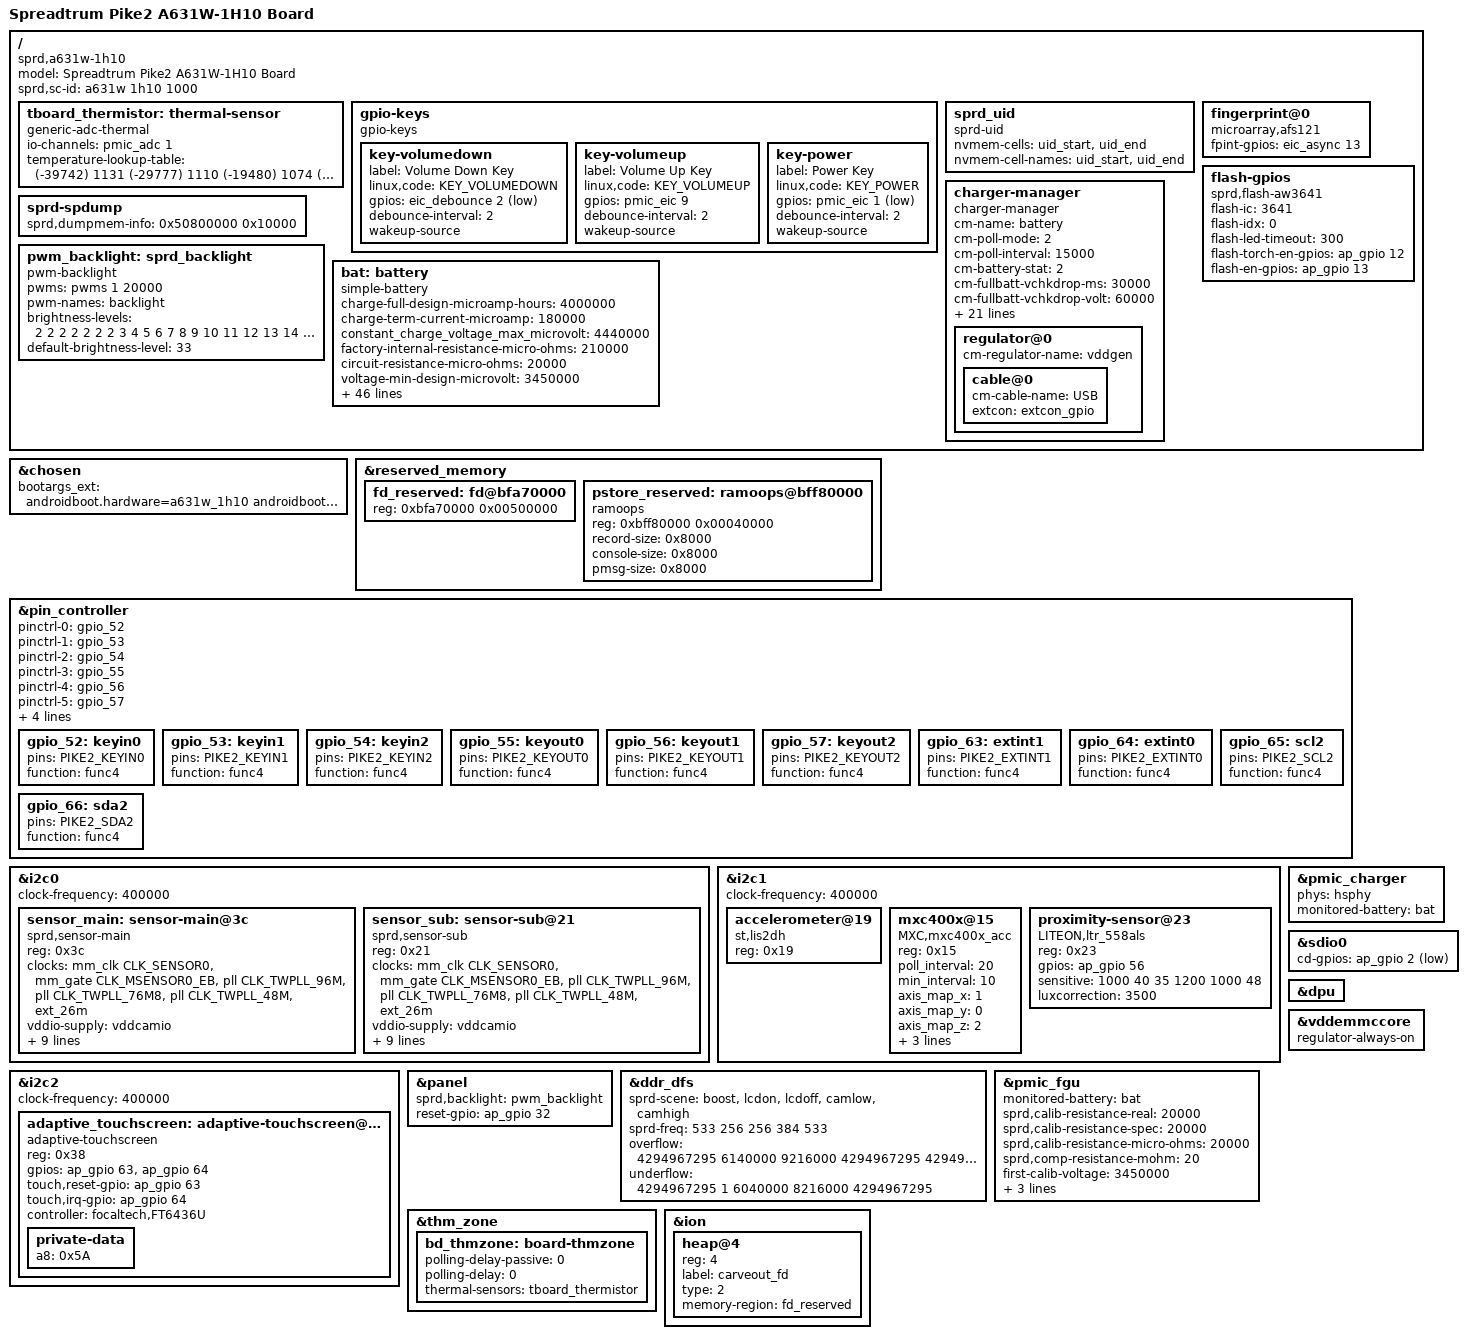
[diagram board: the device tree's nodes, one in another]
/*
 * Spreadtrum sharkle sp7731e board DTS file
 *
 * Copyright (C) 2019, Spreadtrum Communications Inc.
 *
 * This file is licensed under a dual GPLv2 or X11 license.
 */
/dts-v1/;
/plugin/;
#include <dt-bindings/input/input.h>
#include <dt-bindings/gpio/gpio.h>
#include <dt-bindings/clock/sprd,sc7731e-clk.h>
//#include "lcd/lcd_ili9881c_3lane_mipi_fhd.dtsi"
//#include "lcd/lcd_r61350_truly_mipi_hd_v2.dtsi"
#include "lcd/lcd_gc9503NP_mipi_jt.dtsi"
#include "lcd/lcd_dummy_mipi.dtsi"

/ {
	model = "Spreadtrum Pike2 A631W-1H10 Board";

	compatible = "sprd,a631w-1h10", "sprd,sc7731e";

	sprd,sc-id = "a631w 1h10 1000";

	/*
	* When create a new node, we should use the key word __overlay__,
	* otherwise u-boot can not analyze it.
	*/
	fragment {
		target-path = "/";
		__overlay__ {

			tboard_thermistor:thermal-sensor {
				compatible = "generic-adc-thermal";
				#thermal-sensor-cells = <0>;
				io-channels = <&pmic_adc 1>;
				io-channel-names = "sensor-channel";
				temperature-lookup-table = <    (-39742) 1131
								(-29777) 1110
								(-19480) 1074
								(-4679) 983
								10110 838
								24805 654
								44922 413
								54903 316
								64895 238
								74884 178
								84883 133
								94883 100
								104880 75
								114889 57
								124872 43 >;
			};

			gpio-keys {
				compatible = "gpio-keys";

				key-volumedown {
					label = "Volume Down Key";
					linux,code = <KEY_VOLUMEDOWN>;
					gpios = <&eic_debounce 2 GPIO_ACTIVE_LOW>;
					debounce-interval = <2>;
					wakeup-source;
				};

				key-volumeup {
					label = "Volume Up Key";
					linux,code = <KEY_VOLUMEUP>;
					gpios = <&pmic_eic 9 GPIO_ACTIVE_HIGH>;
					debounce-interval = <2>;
					wakeup-source;
				};

				key-power {
					label = "Power Key";
					linux,code = <KEY_POWER>;
					gpios = <&pmic_eic 1 GPIO_ACTIVE_LOW>;
					debounce-interval = <2>;
					wakeup-source;
				};
			};
			sprd_uid {
				compatible = "sprd-uid";
				nvmem-cells = <&uid_start>, <&uid_end>;
				nvmem-cell-names = "uid_start", "uid_end";
			};
			fingerprint@0 {
				compatible = "microarray,afs121";
				fpint-gpios = <&eic_async 13 0>;
			};

			flash-gpios {
				compatible = "sprd,flash-aw3641";
				flash-ic = <3641>;
				flash-idx = <0>;
				flash-led-timeout = <300>;//ms
				flash-torch-en-gpios = <&ap_gpio 12 0>;
				flash-en-gpios = <&ap_gpio 13 0>;
			};

			sprd-spdump {
				sprd,dumpmem-info = <0x50800000 0x10000>;
			};

			pwm_backlight: sprd_backlight {
				compatible = "pwm-backlight";
				pwms = <&pwms 1 20000>;
				pwm-names = "backlight";
				brightness-levels = <
								  2   2   2   2
					  2   2   2   3   4   5   6   7   8   9
					 10  11  12  13  14  15  16  17  18  19
					 20  21  22  23  24  25  26  27  28  29
					 30  31  32  33  34  35  36  37  38  39
					 40  41  42  43  44  45  46  47  48  49
					 50  51  52  53  54  55  56  57  58  59
					 60  61  62  63  64  65  66  67  68  69
					 70  71  72  73  74  75  76  77  78  79
					 80  81  82  83  84  85  86  87  88  89
					 90  91  92  93  94  95  96  97  98  99
					100 101 102 103 104 105 106 107 108 109
					110 111 112 113 114 115 116 117 118 119
					120 121 122 123 124 125 126 127 128 129
					130 131 132 133 134 135 136 137 138 139
					140 141 142 143 144 145 146 147 148 149
					150 151 152 153 154 155 156 157 158 159
					160 161 162 163 164 165 166 167 168 169
					170 171 172 173 174 175 176 177 178 179
					180 181 182 183 184 185 186 187 188 189
					190 191 192 193 194 195 196 197 198 199
					200 201 202 203 204 205 206 207 208 209
					210 211 212 213 214 215 216 217 218 219
					220 221 222 223 224 225 226 227 228 229
					230 231 232 233 234 235 236 237 238 239
					240 241 242 243 244 245 246 247 248 249
					250 251
					>;
				default-brightness-level = <33>;
			};

			bat: battery {
				compatible = "simple-battery";
				charge-full-design-microamp-hours = <4000000>;
				charge-term-current-microamp = <180000>;
				constant_charge_voltage_max_microvolt = <4440000>;
				factory-internal-resistance-micro-ohms = <210000>;
				circuit-resistance-micro-ohms = <20000>;
				voltage-min-design-microvolt = <3450000>;
				fullbatt-voltage = <4350000>;
				fullbatt-current = <180000>;
				fullbatt-track-end-vol = <4295000>;
				fullbatt-track-end-cur = <130000>;
				first-calib-voltage = <3630000>;
				first-calib-capacity = <40>;
				ocv-capacity-celsius = <20>;
				ocv-capacity-table-0 = <4393000 100>, <4326000 95>, <4263000 90>,
							<4193000 85>, <4137000 80>, <4084000 75>,
							<4033000 70>, <3977000 65>, <3937000 60>,
							<3890000 55>, <3844000 50>, <3813000 45>,
							<3794000 40>, <3781000 35>, <3774000 30>,
							<3768000 25>, <3750000 20>, <3729000 15>,
							<3686000 10>, <3588000 5>, <3400000 0>;

				voltage-temp-table = <1066000 800>, <960000 850>, <855000 900>,
							<754000 950>, <660000 1000>, <574000 1050>,
							<497000 1100>, <428000 1150>, <368000 1200>,
							<316000 1250>, <271000 1300>, <232000 1350>,
							<199000 1400>, <170000 1450>, <146000 1500>,
							<126000 1550>, <108000 1600>, <94000 1650>;

				capacity-temp-table = <25 100>, <10 97>, <0 93>, <(-10) 74>;
				resistance-temp-table = <25 100>, <10 186>, <0 324>, <(-10) 608>;
				charge-sdp-current-microamp = <500000 500000>;
				charge-dcp-current-microamp = <1100000 1100000>;
				charge-cdp-current-microamp = <1100000 1100000>;
				charge-unknown-current-microamp = <500000 500000>;

				dcp-jeita-temp-table = <1000 1030 0 4350000>,
					<1150 1180 700000 4350000>,
					<1450 1420 1150000 4350000>,
					<1600 1570 700000 4100000>;
				sdp-jeita-temp-table = <1000 1030 0 4350000>,
					<1150 1180 500000 4350000>,
					<1450 1420 500000 4350000>,
					<1600 1570 500000 4100000>;
				cdp-jeita-temp-table = <1000 1030 0 4350000>,
					<1150 1180 700000 4350000>,
					<1450 1420 1150000 4350000>,
					<1600 1570 700000 4100000>;
				unknown-jeita-temp-table = <1000 1030 0 4350000>,
					<1150 1180 500000 4350000>,
					<1450 1420 500000 4350000>,
					<1600 1570 500000 4100000>;
				force-jeita-status = <2>;
			};

			charger-manager {
				compatible = "charger-manager";
				cm-name = "battery";
				cm-poll-mode = <2>;
				cm-poll-interval = <15000>;
				cm-battery-stat = <2>;

				cm-fullbatt-vchkdrop-ms = <30000>;
				cm-fullbatt-vchkdrop-volt = <60000>;
				cm-fullbatt-capacity = <100>;

				cm-num-chargers = <1>;
				cm-chargers = "sc2720_charger";
				cm-fuel-gauge = "sc27xx-fgu";

				/* in deci centigrade */
				cm-battery-cold = <200>;
				cm-battery-cold-in-minus;
				cm-battery-hot = <800>;
				cm-battery-temp-diff = <100>;

				/* Allow charging for 6hr */
				cm-charging-max = <21600000>;
				/* recovery charging after stop charging 45min */
				cm-discharging-max = <2700000>;

				/* drop voltage in microVolts to allow shutdown */
				cm-shutdown-voltage = <3100000>;

				/* when 99% of the time is exceeded, it will be forced to 100% */
				cm-tickle-time-out = <1500>;

				/* how much time to allow capacity change */
				cm-one-cap-time = <30>;

				cm-thermal-zone = "board-thmzone";

				/* This switch is turned on when chargerIC is charging linearly */
				cm-support-linear-charge;

				/* when the safe charging voltage is exceeded, stop charging */
				cm-charge-voltage-max = <6500000>;
				/* drop voltage in microVolts to restart charging */
				cm-charge-voltage-drop = <700000>;


				monitored-battery = <&bat>;

				/*cm-capacity-track;*/
				transsion-bjt-poll;

				cm-cap-remap-table = <1 2 3>, <2 3 2>, <98 99 2>, <99 100 3>;

				regulator@0 {
					cm-regulator-name = "vddgen";
					cable@0 {
						cm-cable-name = "USB";
						extcon = <&extcon_gpio>;
					};
				};
			};
		};
	};
};

&chosen {
	bootargs_ext = "androidboot.hardware=a631w_1h10 androidboot.dtbo_idx=0 dummy_hcd.num=0";
};

&reserved_memory {
	#address-cells = <1>;
	#size-cells = <1>;

	fd_reserved: fd@bfa70000 {
		reg = <0xbfa70000 0x00500000>;
	};

	pstore_reserved: ramoops@bff80000 {
		compatible = "ramoops";
		reg = <0xbff80000 0x00040000>;
		record-size = <0x8000>;
		console-size = <0x8000>;
		pmsg-size = <0x8000>;
	};
};

&pin_controller {
	pinctrl-names =
	/* keyin0 ~ keyin2 */
	"gpio_52", "gpio_53", "gpio_54",
	/* keyout0 ~ keyout2 */
	"gpio_55", "gpio_56", "gpio_57",
	/* extint1, extint0, scl2, sda2 */
	"gpio_63", "gpio_64", "gpio_65", "gpio_66";
	pinctrl-0 = <&gpio_52>;
	pinctrl-1 = <&gpio_53>;
	pinctrl-2 = <&gpio_54>;
	pinctrl-3 = <&gpio_55>;
	pinctrl-4 = <&gpio_56>;
	pinctrl-5 = <&gpio_57>;
	pinctrl-6 = <&gpio_63>;
	pinctrl-7 = <&gpio_64>;
	pinctrl-8 = <&gpio_65>;
	pinctrl-9 = <&gpio_66>;

	gpio_52: keyin0 {
		pins = "PIKE2_KEYIN0";
		function = "func4";
	};

	gpio_53: keyin1 {
		pins = "PIKE2_KEYIN1";
		function = "func4";
	};

	gpio_54: keyin2 {
		pins = "PIKE2_KEYIN2";
		function = "func4";
	};

	gpio_55: keyout0 {
		pins = "PIKE2_KEYOUT0";
		function = "func4";
	};

	gpio_56: keyout1 {
		pins = "PIKE2_KEYOUT1";
		function = "func4";
	};

	gpio_57: keyout2 {
		pins = "PIKE2_KEYOUT2";
		function = "func4";
	};

	gpio_63: extint1 {
		pins = "PIKE2_EXTINT1";
		function = "func4";
	};

	gpio_64: extint0 {
		pins = "PIKE2_EXTINT0";
		function = "func4";
	};

	gpio_65: scl2 {
		pins = "PIKE2_SCL2";
		function = "func4";
	};

	gpio_66: sda2 {
		pins = "PIKE2_SDA2";
		function = "func4";
	};
};

&i2c0 {
	status = "okay";
	clock-frequency = <400000>;
	#address-cells = <1>;
	#size-cells = <0>;

	sensor_main: sensor-main@3c {
		compatible = "sprd,sensor-main";
		reg = <0x3c>;
		clock-names = "clk_src", "sensor_eb",
			"clk_96m", "clk_76m8",
			"clk_48m", "clk_26m";
		clocks  = <&mm_clk CLK_SENSOR0>,
			<&mm_gate CLK_MSENSOR0_EB>,
			<&pll CLK_TWPLL_96M>,
			<&pll CLK_TWPLL_76M8>,
			<&pll CLK_TWPLL_48M>,
			<&ext_26m>;
		vddio-supply = <&vddcamio>;
		vddcama-supply = <&vddcama>;
		vddcamd-supply = <&vddcamd>;
		vddcammot-supply = <&vddcammot>;
		reset-gpios = <&ap_gpio 37 0>;
		power-down-gpios = <&ap_gpio 38 0>;
		host = "dcam0";
		sprd,phyid = <0>;
		csi = <&csi0>;
		power-domains = <&cam_domain>;
	};

	sensor_sub: sensor-sub@21 {
		compatible = "sprd,sensor-sub";
		reg = <0x21>;
		clock-names = "clk_src","sensor_eb",
			"clk_96m", "clk_76m8",
			"clk_48m", "clk_26m";
		clocks = <&mm_clk CLK_SENSOR0>,
			<&mm_gate CLK_MSENSOR0_EB>,
			<&pll CLK_TWPLL_96M>,
			<&pll CLK_TWPLL_76M8>,
			<&pll CLK_TWPLL_48M>,
			<&ext_26m>;
		vddio-supply = <&vddcamio>;
		vddcama-supply = <&vddcama>;
		vddcamd-supply = <&vddcamd>;
		vddcammot-supply = <&vddcammot>;
		reset-gpios = <&ap_gpio 18 0>;
		power-down-gpios = <&ap_gpio 39 0>;
		host = "dcam0";
		sprd,phyid = <0>;
		csi = <&csi0>;
		power-domains = <&cam_domain>;
	};
};

&i2c1 {
	status = "okay";
	clock-frequency = <400000>;
	#address-cells = <1>;
	#size-cells = <0>;

	accelerometer@19 {
		compatible = "st,lis2dh", "st,lis2dh12";
		reg = <0x19>;
	};
	mxc400x@15 {
		compatible = "MXC,mxc400x_acc";
		reg = <0x15>;
		poll_interval = <20>;
		min_interval = <10>;
		axis_map_x = <1>;
		axis_map_y = <0>;
		axis_map_z = <2>;
		negate_x = <0>;
		negate_y = <0>;
		negate_z = <1>;
	};

	proximity-sensor@23 {
		compatible = "LITEON,ltr_558als";
		reg = <0x23>;
		gpios = <&ap_gpio 56 GPIO_ACTIVE_HIGH>;
		/*
		 *low sensitve(def):1500,250,220,1800,1600,1;
		 *have no sensitve=<> as def.
		 * High sensitve:1000,40,35,1200,1000,48
		 */
		sensitive = <1000 40 35
					1200 1000 48>;
		luxcorrection = <3500>;
	};
};

&i2c2 {
	status = "okay";
	clock-frequency = <400000>;
	#address-cells = <1>;
	#size-cells = <0>;

	adaptive_touchscreen:adaptive-touchscreen@38 {
		status = "okay";
		compatible = "adaptive-touchscreen";
		reg = <0x38>;
		gpios = <&ap_gpio 63 GPIO_ACTIVE_HIGH
			&ap_gpio 64 GPIO_ACTIVE_HIGH>;

		touch,reset-gpio = <&ap_gpio 63 0>;
		touch,irq-gpio= <&ap_gpio 64 0>;

		controller = "focaltech,FT6436U";

		private-data {
			a8 = /bits/ 8 <0x5A>;
		};
	};
};

#include "aw631tp_param.dtsi"

&panel {
	sprd,backlight = <&pwm_backlight>;
	reset-gpio = <&ap_gpio 32 GPIO_ACTIVE_HIGH>;
};

&ddr_dfs {
	sprd-scene = "boost", "lcdon", "lcdoff", "camlow", "camhigh";
	sprd-freq = <533 256 256 384 533>;
	overflow = <4294967295 6140000 9216000 4294967295 4294967295>;
	underflow = <4294967295 1 6040000 8216000 4294967295>;
};

&pmic_charger {
	status = "okay";
	phys = <&hsphy>;
	monitored-battery = <&bat>;
};

&pmic_fgu {
	monitored-battery = <&bat>;
	sprd,calib-resistance-real = <20000>;
	sprd,calib-resistance-spec = <20000>;
	sprd,calib-resistance-micro-ohms = <20000>;
	sprd,comp-resistance-mohm = <20>;
	first-calib-voltage = <3450000>;
	first-calib-capacity = <40>;

	fgu-capacity-track;
	phys = <&hsphy>;
};

&sdio0 {
	cd-gpios = <&ap_gpio 2 1>;
};

&thm_zone {
	bd_thmzone: board-thmzone {
		polling-delay-passive = <0>;
		polling-delay = <0>;
		thermal-sensors = <&tboard_thermistor>;
	};
};

&dpu {
	status = "okay";
	/*sprd,wb-memory = <&wb_reserved>;*/
};

&ion {
	#address-cells = <1>;
	#size-cells = <0>;

	heap@4 {
		reg = <4>;
		label = "carveout_fd";
		type = <2>;
		memory-region = <&fd_reserved>;
	};
};

&vddemmccore {
	regulator-always-on;
};
